AUTOSAR XML (schema 4-2-2)
standard types defined: uint8, uint16, float32
package /DataTypes  # 数据类型定义 | 包含应用程序使用的所有数据类型定义
  impl type Speed_kph: category=VALUE  # 速度（公里/小时） | 车辆速度数据类型，单位为公里每小时
  impl type Temperature_degC: category=VALUE  # 温度（摄氏度）
  unit kph: display-name=km/h  # Kilometers per hour
  unit degC: display-name=°C
  compu method CM_Speed: linear
package /Interfaces  # 软件组件接口定义
  sender receiver interface IF_VehicleSpeed  # 车辆速度接口 | 用于传输车辆速度信息的发送接收接口
    data CurrentSpeed: type=/DataTypes/Speed_kph
  sender receiver interface IF_EngineTemperature  # 发动机温度接口
    data EngineTemp: type=/DataTypes/Temperature_degC
  client server interface IF_DiagnosticService  # 诊断服务接口 | 提供车辆诊断功能的客户端服务端接口
    operation ReadDTC
      arg dtcId: direction=IN, type=/DataTypes/uint16
      arg dtcStatus: direction=OUT, type=/DataTypes/uint8
    operation ClearDTC
      arg dtcId: direction=IN, type=/DataTypes/uint16
package /SwComponents  # 软件组件定义
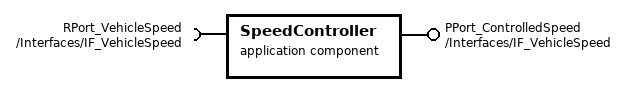
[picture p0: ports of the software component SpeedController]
  application sw component type SpeedController  # 速度控制器 | 负责车辆速度控制的应用软件组件
    require port RPort_VehicleSpeed: required-interface=/Interfaces/IF_VehicleSpeed
    provide port PPort_ControlledSpeed: provided-interface=/Interfaces/IF_VehicleSpeed
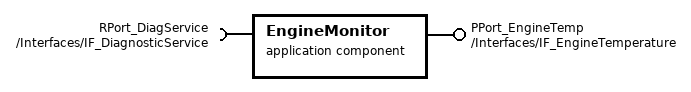
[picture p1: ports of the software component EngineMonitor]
  application sw component type EngineMonitor  # 发动机监控 | 监控发动机状态的应用软件组件
    provide port PPort_EngineTemp: provided-interface=/Interfaces/IF_EngineTemperature
    require port RPort_DiagService: required-interface=/Interfaces/IF_DiagnosticService
  application sw component type DiagnosticHandler  # 诊断处理器
    provide port PPort_DiagService: provided-interface=/Interfaces/IF_DiagnosticService
